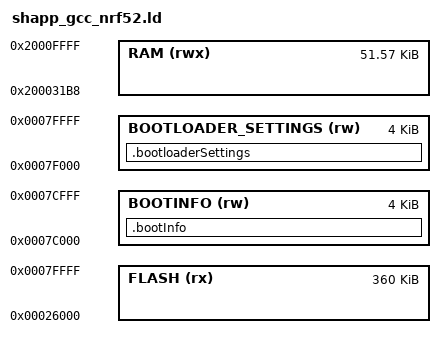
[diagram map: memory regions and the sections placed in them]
/* Linker script to configure memory regions. */

SEARCH_DIR(.)
GROUP(-lgcc -lc -lnosys)

MEMORY
{
  FLASH (rx) : ORIGIN = 0x26000, LENGTH = 0x5a000
  RAM (rwx) :  ORIGIN = 0x200031b8, LENGTH = 0xce48

  /** Location of boot settings */
  BOOTINFO (rw) : ORIGIN = 0x0007C000, LENGTH = 0x1000

  /** Location of bootloader setting in flash. */
  BOOTLOADER_SETTINGS (rw) : ORIGIN = 0x0007F000, LENGTH = 0x1000

}

SECTIONS
{
  /* Place the boot settings page in flash. */
  .bootInfo(NOLOAD) :
  {

  } > BOOTINFO
  /* Place the bootloader settings page in flash. */
  .bootloaderSettings(NOLOAD) :
  {

  } > BOOTLOADER_SETTINGS
}

SECTIONS
{
  .fs_data :
  {
    PROVIDE(__start_fs_data = .);
    KEEP(*(.fs_data))
    PROVIDE(__stop_fs_data = .);
  } > RAM
} INSERT AFTER .data;

SECTIONS
{
  .mem_section_dummy_rom :
  {
  }
  .sdh_soc_observers :
  {
    PROVIDE(__start_sdh_soc_observers = .);
    KEEP(*(SORT(.sdh_soc_observers*)))
    PROVIDE(__stop_sdh_soc_observers = .);
  } > FLASH
  .sdh_ble_observers :
  {
    PROVIDE(__start_sdh_ble_observers = .);
    KEEP(*(SORT(.sdh_ble_observers*)))
    PROVIDE(__stop_sdh_ble_observers = .);
  } > FLASH
  .sdh_state_observers :
  {
    PROVIDE(__start_sdh_state_observers = .);
    KEEP(*(SORT(.sdh_state_observers*)))
    PROVIDE(__stop_sdh_state_observers = .);
  } > FLASH
  .sdh_stack_observers :
  {
    PROVIDE(__start_sdh_stack_observers = .);
    KEEP(*(SORT(.sdh_stack_observers*)))
    PROVIDE(__stop_sdh_stack_observers = .);
  } > FLASH
  .sdh_req_observers :
  {
    PROVIDE(__start_sdh_req_observers = .);
    KEEP(*(SORT(.sdh_req_observers*)))
    PROVIDE(__stop_sdh_req_observers = .);
  } > FLASH
  .log_const_data :
  {
    PROVIDE(__start_log_const_data = .);
    KEEP(*(SORT(.log_const_data*)))
    PROVIDE(__stop_log_const_data = .);
  } > FLASH
  .log_backends :
  {
    PROVIDE(__start_log_backends = .);
    KEEP(*(SORT(.log_backends*)))
    PROVIDE(__stop_log_backends = .);
  } > FLASH
    .nrf_balloc :
  {
    PROVIDE(__start_nrf_balloc = .);
    KEEP(*(.nrf_balloc))
    PROVIDE(__stop_nrf_balloc = .);
  } > FLASH

} INSERT AFTER .text

INCLUDE "nrf_common.ld"
